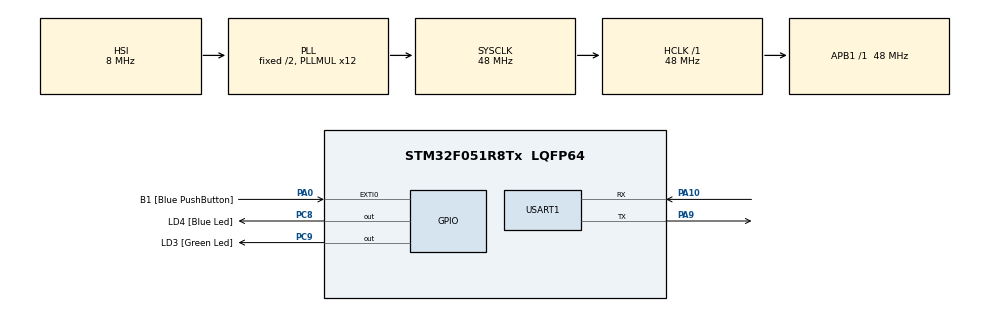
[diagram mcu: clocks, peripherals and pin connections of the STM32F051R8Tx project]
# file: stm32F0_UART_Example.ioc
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Mcu.Family=STM32F0
Mcu.Name=STM32F051R8Tx
Mcu.Package=LQFP64
PA0.GPIO_Label=B1 [Blue PushButton]
PA0.GPIO_ModeDefaultEXTI=GPIO_MODE_EVT_RISING
PA0.Signal=GPXTI0
PA10.Mode=Asynchronous
PA10.Signal=USART1_RX
PA13.GPIO_Label=SWDIO
PA13.Mode=Serial_Wire
PA13.Signal=SYS_SWDIO
PA14.GPIO_Label=SWCLK
PA14.Mode=Serial_Wire
PA14.Signal=SYS_SWCLK
PA9.Mode=Asynchronous
PA9.Signal=USART1_TX
PC8.GPIO_Label=LD4 [Blue Led]
PC8.Signal=GPIO_Output
PC9.GPIO_Label=LD3 [Green Led]
PC9.Signal=GPIO_Output
ProjectManager.HeapSize=0x200
ProjectManager.StackSize=0x400
ProjectManager.TargetToolchain=STM32CubeIDE
RCC.AHBFreq_Value=48000000
RCC.APB1Freq_Value=48000000
RCC.APB1TimFreq_Value=48000000
RCC.HCLKFreq_Value=48000000
RCC.PLLMUL=RCC_PLL_MUL12
RCC.SYSCLKFreq_VALUE=48000000
RCC.SYSCLKSource=RCC_SYSCLKSOURCE_PLLCLK
USART1.VirtualMode-Asynchronous=VM_ASYNC
board=STM32F0DISCOVERY

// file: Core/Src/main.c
/* USER CODE BEGIN Header */
/**
  ******************************************************************************
  * @file           : main.c
  * @brief          : Main program body
  ******************************************************************************
  * @attention
  *
  * <h2><center>&copy; Copyright (c) 2022 STMicroelectronics.
  * All rights reserved.</center></h2>
  *
  * This software component is licensed by ST under BSD 3-Clause license,
  * the "License"; You may not use this file except in compliance with the
  * License. You may obtain a copy of the License at:
  *                        opensource.org/licenses/BSD-3-Clause
  *
  ******************************************************************************
  */
/* USER CODE END Header */

#include "main.h"
#include "usart.h"
#include "gpio.h"

void SystemClock_Config(void);

int main(void)
{

  /* MCU Configuration--------------------------------------------------------*/

  /* Reset of all peripherals, Initializes the Flash interface and the Systick. */
  HAL_Init();

  /* Configure the system clock */
  SystemClock_Config();

  /* Initialize all configured peripherals */
  MX_GPIO_Init();
  MX_USART1_UART_Init();
  /* USER CODE BEGIN 2 */
  char *str = "Hello World";
  /* USER CODE END 2 */

  /* Infinite loop */
  /* USER CODE BEGIN WHILE */
  while (1)
  {
	  HAL_UART_Transmit(huart, str, strlen(str), 1000);
    /* USER CODE END WHILE */

  }
}

void SystemClock_Config(void)
{
  RCC_OscInitTypeDef RCC_OscInitStruct = {0};
  RCC_ClkInitTypeDef RCC_ClkInitStruct = {0};
  RCC_PeriphCLKInitTypeDef PeriphClkInit = {0};

  /** Initializes the CPU, AHB and APB busses clocks
  */
  RCC_OscInitStruct.OscillatorType = RCC_OSCILLATORTYPE_HSI;
  RCC_OscInitStruct.HSIState = RCC_HSI_ON;
  RCC_OscInitStruct.HSICalibrationValue = RCC_HSICALIBRATION_DEFAULT;
  RCC_OscInitStruct.PLL.PLLState = RCC_PLL_ON;
  RCC_OscInitStruct.PLL.PLLSource = RCC_PLLSOURCE_HSI;
  RCC_OscInitStruct.PLL.PLLMUL = RCC_PLL_MUL12;
  RCC_OscInitStruct.PLL.PREDIV = RCC_PREDIV_DIV1;
  if (HAL_RCC_OscConfig(&RCC_OscInitStruct) != HAL_OK)
  {
    Error_Handler();
  }
  /** Initializes the CPU, AHB and APB busses clocks
  */
  RCC_ClkInitStruct.ClockType = RCC_CLOCKTYPE_HCLK|RCC_CLOCKTYPE_SYSCLK
                              |RCC_CLOCKTYPE_PCLK1;
  RCC_ClkInitStruct.SYSCLKSource = RCC_SYSCLKSOURCE_PLLCLK;
  RCC_ClkInitStruct.AHBCLKDivider = RCC_SYSCLK_DIV1;
  RCC_ClkInitStruct.APB1CLKDivider = RCC_HCLK_DIV1;

  if (HAL_RCC_ClockConfig(&RCC_ClkInitStruct, FLASH_LATENCY_1) != HAL_OK)
  {
    Error_Handler();
  }
  PeriphClkInit.PeriphClockSelection = RCC_PERIPHCLK_USART1;
  PeriphClkInit.Usart1ClockSelection = RCC_USART1CLKSOURCE_PCLK1;
  if (HAL_RCCEx_PeriphCLKConfig(&PeriphClkInit) != HAL_OK)
  {
    Error_Handler();
  }
}

void Error_Handler(void)
{
}

/************************ (C) COPYRIGHT STMicroelectronics *****END OF FILE****/
